# N32L406 register map
Vendor: Nationstech Ltd.; File version: 1.0
Registers are 32-bit, read-write, reset 0x0 unless marked. A register's access mark holds for its fields unless they carry their own. Offsets are from the block's base; [hi:lo] are bit positions; lines under a group give offsets from that group; {n}, {i} and the like mark numbered series.

## NVIC — Nested Vectored Interrupt Controller registers
Base 0xE000E004
0x00 ICTR ro — Provides information about the interrupt controller
  [3:0] INTLINESNUM — The total number of interrupt lines supported n, defined in groups of 32. That is, the total number of interrupt lines is up to (32*(INTLINESNUM+1)). However, the absolute maximum number of interrupts is 496, corresponding to the INTLINESNUM value 0b1111.
0x252 NVIC_ISER0 — Enables, or reads the enable state of a group of interrupts
0x256 NVIC_ISER1 — Enables, or reads the enable state of a group of interrupts
{0x258+4i} NVIC_ISER{i} (i=2..4) — Enables, or reads the enable state of a group of interrupts
0x272 NVIC_ISER5 — Enables, or reads the enable state of a group of interrupts
0x276 NVIC_ISER6 — Enables, or reads the enable state of a group of interrupts
0x280 NVIC_ISER7 — Enables, or reads the enable state of a group of interrupts
{0x380+4i} NVIC_ICER{i} (i=0..2) — Disables, or reads the enable state of a group of interrupts
0x392 NVIC_ICER3 — Disables, or reads the enable state of a group of interrupts
0x396 NVIC_ICER4 — Disables, or reads the enable state of a group of interrupts
{0x3EC+4i} NVIC_ICER{i} (i=5..7) — Disables, or reads the enable state of a group of interrupts
0x508 NVIC_ISPR0 — For a group of interrupts, changes interrupt status to pending, or shows the current pending status
0x512 NVIC_ISPR1 — For a group of interrupts, changes interrupt status to pending, or shows the current pending status
0x516 NVIC_ISPR2 — For a group of interrupts, changes interrupt status to pending, or shows the current pending status
{0x514+4i} NVIC_ISPR{i} (i=3..5) — For a group of interrupts, changes interrupt status to pending, or shows the current pending status
0x532 NVIC_ISPR6 — For a group of interrupts, changes interrupt status to pending, or shows the current pending status
0x536 NVIC_ISPR7 — For a group of interrupts, changes interrupt status to pending, or shows the current pending status
0x636 NVIC_ICPR0 — For a group of interrupts, clears the interrupt pending status, or shows the current pending status
{0x63C+4i} NVIC_ICPR{i} (i=1..3) — For a group of interrupts, clears the interrupt pending status, or shows the current pending status
0x652 NVIC_ICPR4 — For a group of interrupts, clears the interrupt pending status, or shows the current pending status
0x656 NVIC_ICPR5 — For a group of interrupts, clears the interrupt pending status, or shows the current pending status
0x660 NVIC_ICPR6 — For a group of interrupts, clears the interrupt pending status, or shows the current pending status
0x664 NVIC_ICPR7 — For a group of interrupts, clears the interrupt pending status, or shows the current pending status
0x764 NVIC_IABR0 — For a group of 32 interrupts, shows whether each interrupt is active
0x768 NVIC_IABR1 — For a group of 32 interrupts, shows whether each interrupt is active
0x772 NVIC_IABR2 — For a group of 32 interrupts, shows whether each interrupt is active
0x776 NVIC_IABR3 — For a group of 32 interrupts, shows whether each interrupt is active
{0x770+4i} NVIC_IABR{i} (i=4..6) — For a group of 32 interrupts, shows whether each interrupt is active
0x792 NVIC_IABR7 — For a group of 32 interrupts, shows whether each interrupt is active
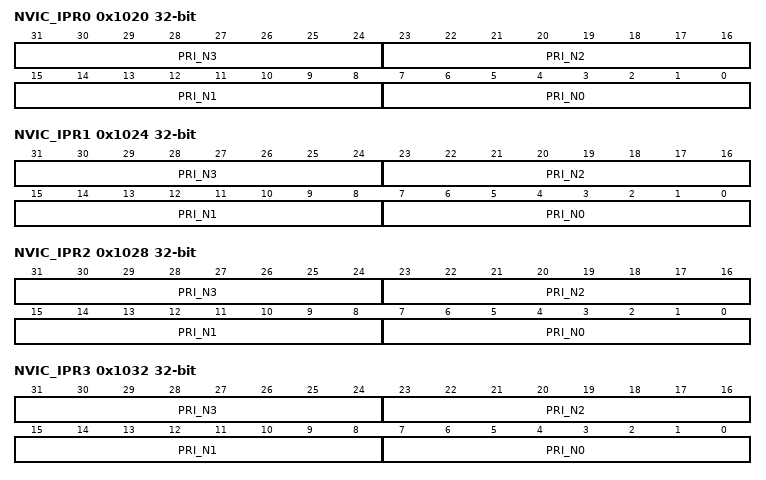
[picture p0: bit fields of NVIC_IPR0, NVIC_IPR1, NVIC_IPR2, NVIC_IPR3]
0x1020 NVIC_IPR0 — Sets or reads interrupt priorities
  [8n+7:8n] PRI_N{n} (n=0..3) — Priority of interrupt {n}
0x1024 NVIC_IPR1 — Sets or reads interrupt priorities
  [8n+7:8n] PRI_N{n} (n=0..3) — Priority of interrupt {n+4}
0x1028 NVIC_IPR2 — Sets or reads interrupt priorities
  [8n+7:8n] PRI_N{n} (n=0..3) — Priority of interrupt {n+8}
0x1032 NVIC_IPR3 — Sets or reads interrupt priorities
  [8n+7:8n] PRI_N{n} (n=0..3) — Priority of interrupt {n+12}
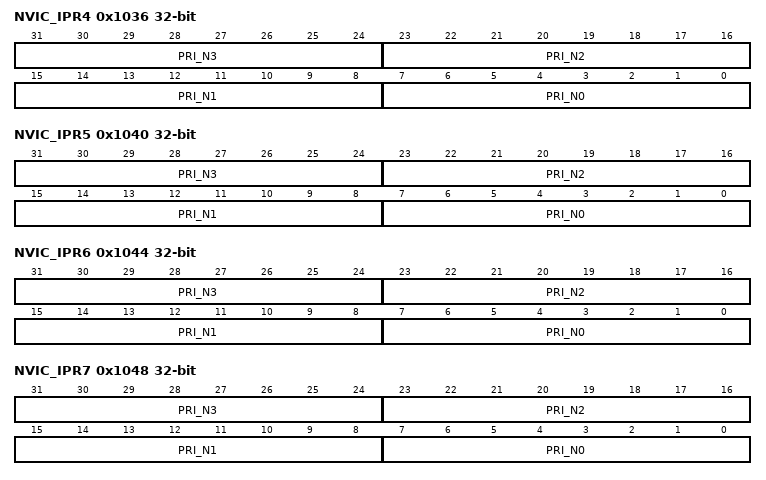
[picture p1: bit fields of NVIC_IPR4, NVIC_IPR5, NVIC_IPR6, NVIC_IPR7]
0x1036 NVIC_IPR4 — Sets or reads interrupt priorities
  [8n+7:8n] PRI_N{n} (n=0..3) — Priority of interrupt {n+16}
0x1040 NVIC_IPR5 — Sets or reads interrupt priorities
  [8n+7:8n] PRI_N{n} (n=0..3) — Priority of interrupt {n+20}
0x1044 NVIC_IPR6 — Sets or reads interrupt priorities
  [8n+7:8n] PRI_N{n} (n=0..3) — Priority of interrupt {n+24}
0x1048 NVIC_IPR7 — Sets or reads interrupt priorities
  [8n+7:8n] PRI_N{n} (n=0..3) — Priority of interrupt {n+28}
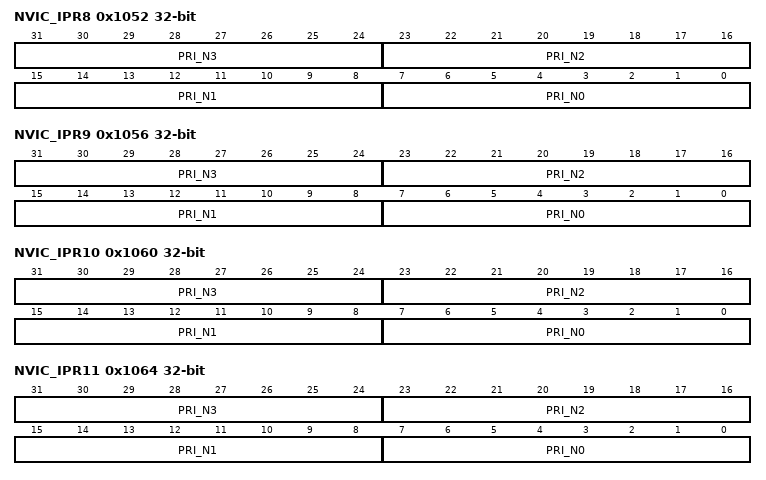
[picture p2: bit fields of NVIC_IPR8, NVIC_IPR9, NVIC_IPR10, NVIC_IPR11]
0x1052 NVIC_IPR8 — Sets or reads interrupt priorities
  [8n+7:8n] PRI_N{n} (n=0..3) — Priority of interrupt {n+32}
0x1056 NVIC_IPR9 — Sets or reads interrupt priorities
  [8n+7:8n] PRI_N{n} (n=0..3) — Priority of interrupt {n+36}
0x1060 NVIC_IPR10 — Sets or reads interrupt priorities
  [8n+7:8n] PRI_N{n} (n=0..3) — Priority of interrupt {n+40}
0x1064 NVIC_IPR11 — Sets or reads interrupt priorities
  [8n+7:8n] PRI_N{n} (n=0..3) — Priority of interrupt {n+44}
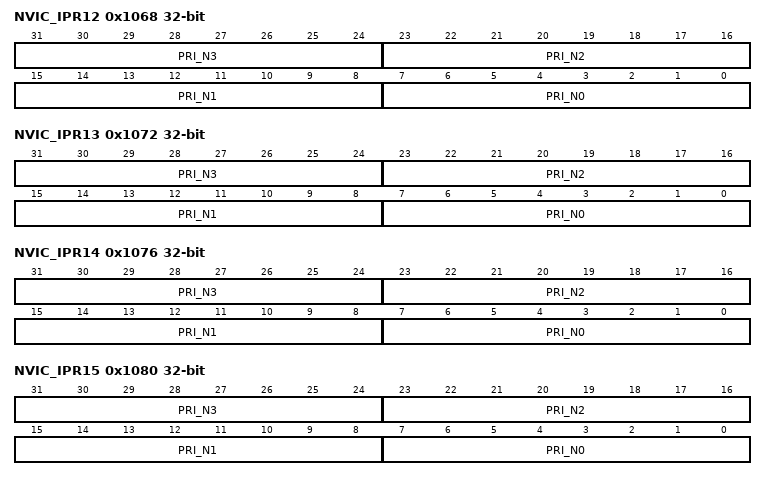
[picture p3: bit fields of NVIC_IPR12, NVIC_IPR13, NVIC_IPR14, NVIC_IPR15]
0x1068 NVIC_IPR12 — Sets or reads interrupt priorities
  [8n+7:8n] PRI_N{n} (n=0..3) — Priority of interrupt {n+48}
0x1072 NVIC_IPR13 — Sets or reads interrupt priorities
  [8n+7:8n] PRI_N{n} (n=0..3) — Priority of interrupt {n+52}
0x1076 NVIC_IPR14 — Sets or reads interrupt priorities
  [8n+7:8n] PRI_N{n} (n=0..3) — Priority of interrupt {n+56}
0x1080 NVIC_IPR15 — Sets or reads interrupt priorities
  [8n+7:8n] PRI_N{n} (n=0..3) — Priority of interrupt {n+60}
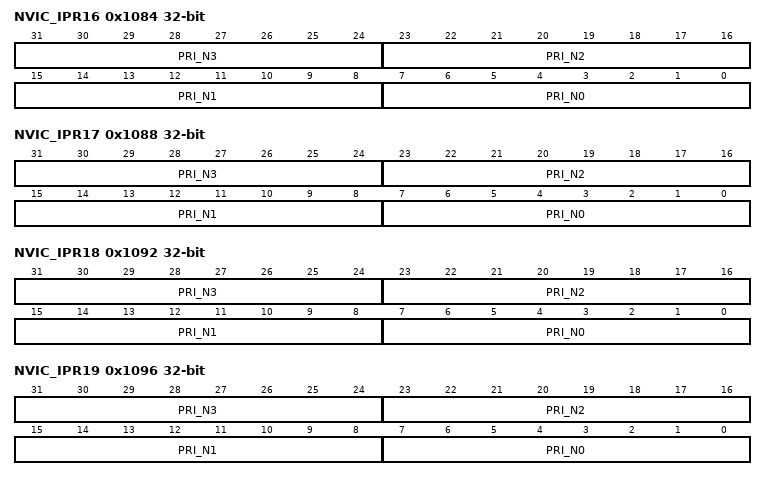
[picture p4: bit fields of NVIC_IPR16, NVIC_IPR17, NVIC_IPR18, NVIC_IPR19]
0x1084 NVIC_IPR16 — Sets or reads interrupt priorities
  [8n+7:8n] PRI_N{n} (n=0..3) — Priority of interrupt {n+64}
0x1088 NVIC_IPR17 — Sets or reads interrupt priorities
  [8n+7:8n] PRI_N{n} (n=0..3) — Priority of interrupt {n+68}
0x1092 NVIC_IPR18 — Sets or reads interrupt priorities
  [8n+7:8n] PRI_N{n} (n=0..3) — Priority of interrupt {n+72}
0x1096 NVIC_IPR19 — Sets or reads interrupt priorities
  [8n+7:8n] PRI_N{n} (n=0..3) — Priority of interrupt {n+76}
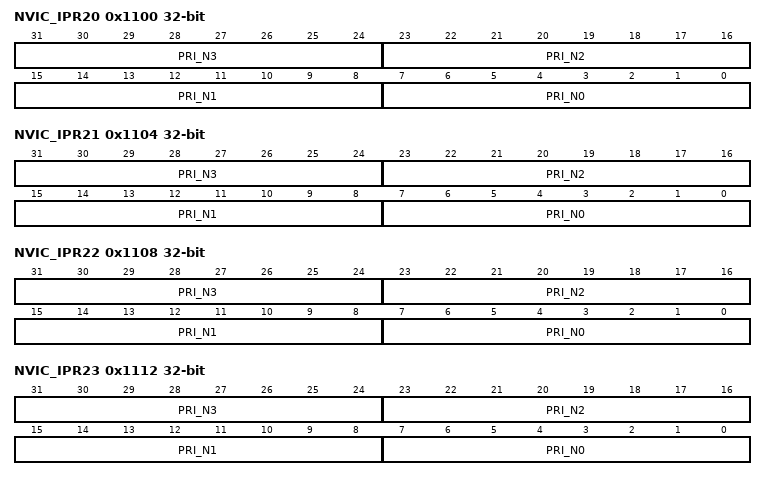
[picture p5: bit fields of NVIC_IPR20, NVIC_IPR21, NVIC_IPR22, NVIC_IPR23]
0x1100 NVIC_IPR20 — Sets or reads interrupt priorities
  [8n+7:8n] PRI_N{n} (n=0..3) — Priority of interrupt {n+80}
0x1104 NVIC_IPR21 — Sets or reads interrupt priorities
  [8n+7:8n] PRI_N{n} (n=0..3) — Priority of interrupt {n+84}
0x1108 NVIC_IPR22 — Sets or reads interrupt priorities
  [8n+7:8n] PRI_N{n} (n=0..3) — Priority of interrupt {n+88}
0x1112 NVIC_IPR23 — Sets or reads interrupt priorities
  [8n+7:8n] PRI_N{n} (n=0..3) — Priority of interrupt {n+92}
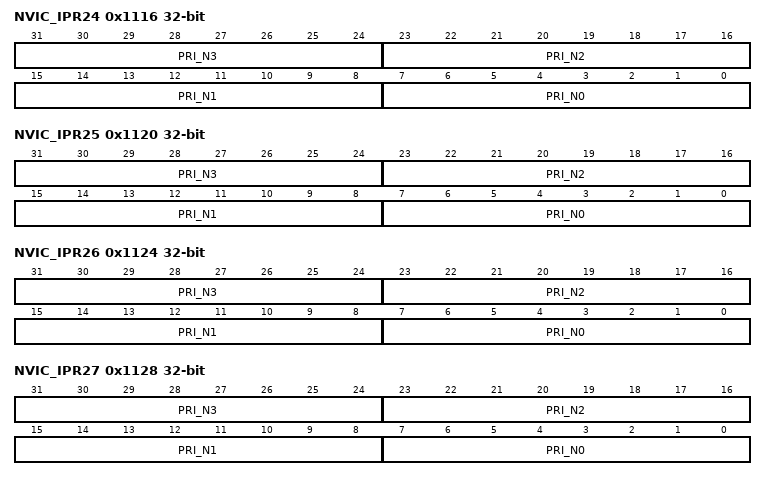
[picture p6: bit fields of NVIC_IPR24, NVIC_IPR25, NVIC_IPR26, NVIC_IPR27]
0x1116 NVIC_IPR24 — Sets or reads interrupt priorities
  [8n+7:8n] PRI_N{n} (n=0..3) — Priority of interrupt {n+96}
0x1120 NVIC_IPR25 — Sets or reads interrupt priorities
  [8n+7:8n] PRI_N{n} (n=0..3) — Priority of interrupt {n+100}
0x1124 NVIC_IPR26 — Sets or reads interrupt priorities
  [8n+7:8n] PRI_N{n} (n=0..3) — Priority of interrupt {n+104}
0x1128 NVIC_IPR27 — Sets or reads interrupt priorities
  [8n+7:8n] PRI_N{n} (n=0..3) — Priority of interrupt {n+108}
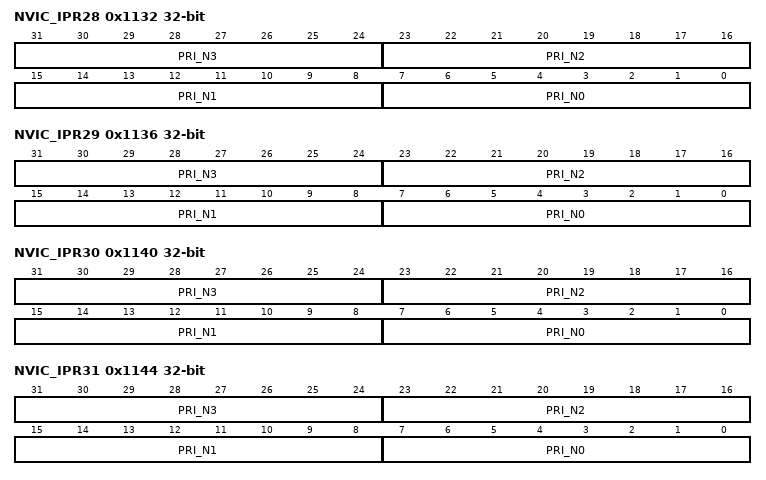
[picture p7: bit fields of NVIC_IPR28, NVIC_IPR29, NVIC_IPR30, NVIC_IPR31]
0x1132 NVIC_IPR28 — Sets or reads interrupt priorities
  [8n+7:8n] PRI_N{n} (n=0..3) — Priority of interrupt {n+112}
0x1136 NVIC_IPR29 — Sets or reads interrupt priorities
  [8n+7:8n] PRI_N{n} (n=0..3) — Priority of interrupt {n+116}
0x1140 NVIC_IPR30 — Sets or reads interrupt priorities
  [8n+7:8n] PRI_N{n} (n=0..3) — Priority of interrupt {n+120}
0x1144 NVIC_IPR31 — Sets or reads interrupt priorities
  [8n+7:8n] PRI_N{n} (n=0..3) — Priority of interrupt {n+124}
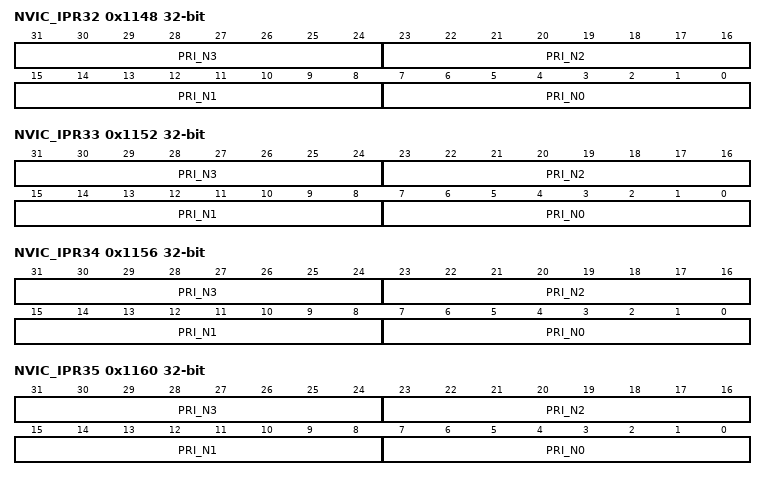
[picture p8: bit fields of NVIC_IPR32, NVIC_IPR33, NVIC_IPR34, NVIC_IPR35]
0x1148 NVIC_IPR32 — Sets or reads interrupt priorities
  [8n+7:8n] PRI_N{n} (n=0..3) — Priority of interrupt {n+128}
0x1152 NVIC_IPR33 — Sets or reads interrupt priorities
  [8n+7:8n] PRI_N{n} (n=0..3) — Priority of interrupt {n+132}
0x1156 NVIC_IPR34 — Sets or reads interrupt priorities
  [8n+7:8n] PRI_N{n} (n=0..3) — Priority of interrupt {n+136}
0x1160 NVIC_IPR35 — Sets or reads interrupt priorities
  [8n+7:8n] PRI_N{n} (n=0..3) — Priority of interrupt {n+140}
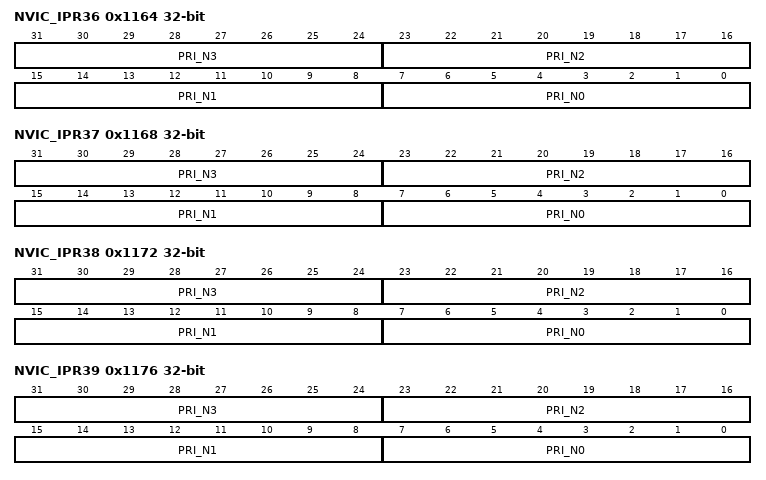
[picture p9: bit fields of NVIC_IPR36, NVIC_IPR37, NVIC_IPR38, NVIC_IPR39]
0x1164 NVIC_IPR36 — Sets or reads interrupt priorities
  [8n+7:8n] PRI_N{n} (n=0..3) — Priority of interrupt {n+144}
0x1168 NVIC_IPR37 — Sets or reads interrupt priorities
  [8n+7:8n] PRI_N{n} (n=0..3) — Priority of interrupt {n+148}
0x1172 NVIC_IPR38 — Sets or reads interrupt priorities
  [8n+7:8n] PRI_N{n} (n=0..3) — Priority of interrupt {n+152}
0x1176 NVIC_IPR39 — Sets or reads interrupt priorities
  [8n+7:8n] PRI_N{n} (n=0..3) — Priority of interrupt {n+156}
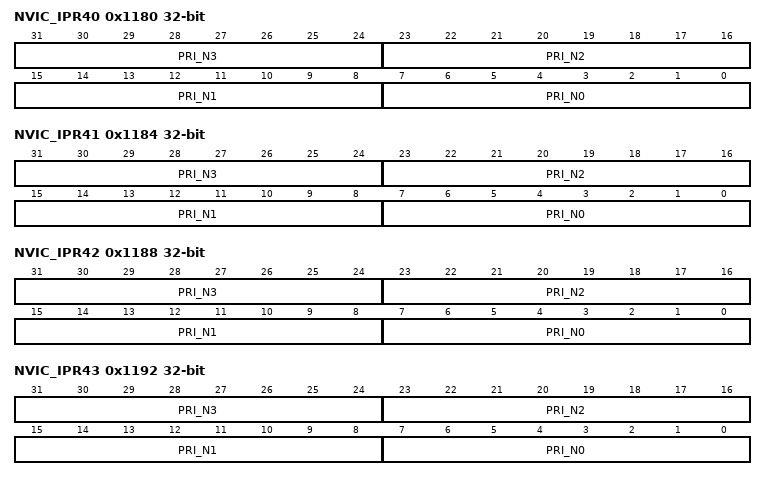
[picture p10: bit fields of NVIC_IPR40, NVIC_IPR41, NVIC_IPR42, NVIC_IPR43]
0x1180 NVIC_IPR40 — Sets or reads interrupt priorities
  [8n+7:8n] PRI_N{n} (n=0..3) — Priority of interrupt {n+160}
0x1184 NVIC_IPR41 — Sets or reads interrupt priorities
  [8n+7:8n] PRI_N{n} (n=0..3) — Priority of interrupt {n+164}
0x1188 NVIC_IPR42 — Sets or reads interrupt priorities
  [8n+7:8n] PRI_N{n} (n=0..3) — Priority of interrupt {n+168}
0x1192 NVIC_IPR43 — Sets or reads interrupt priorities
  [8n+7:8n] PRI_N{n} (n=0..3) — Priority of interrupt {n+172}
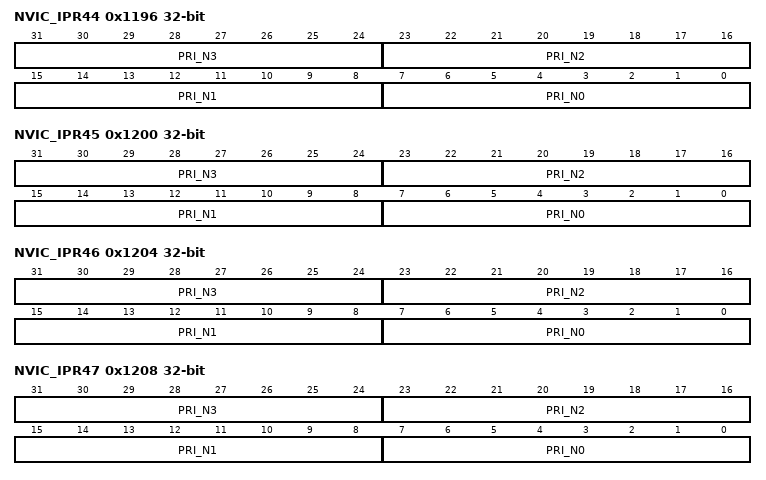
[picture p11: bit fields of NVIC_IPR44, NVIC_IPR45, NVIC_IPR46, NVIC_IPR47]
0x1196 NVIC_IPR44 — Sets or reads interrupt priorities
  [8n+7:8n] PRI_N{n} (n=0..3) — Priority of interrupt {n+176}
0x1200 NVIC_IPR45 — Sets or reads interrupt priorities
  [8n+7:8n] PRI_N{n} (n=0..3) — Priority of interrupt {n+180}
0x1204 NVIC_IPR46 — Sets or reads interrupt priorities
  [8n+7:8n] PRI_N{n} (n=0..3) — Priority of interrupt {n+184}
0x1208 NVIC_IPR47 — Sets or reads interrupt priorities
  [8n+7:8n] PRI_N{n} (n=0..3) — Priority of interrupt {n+188}
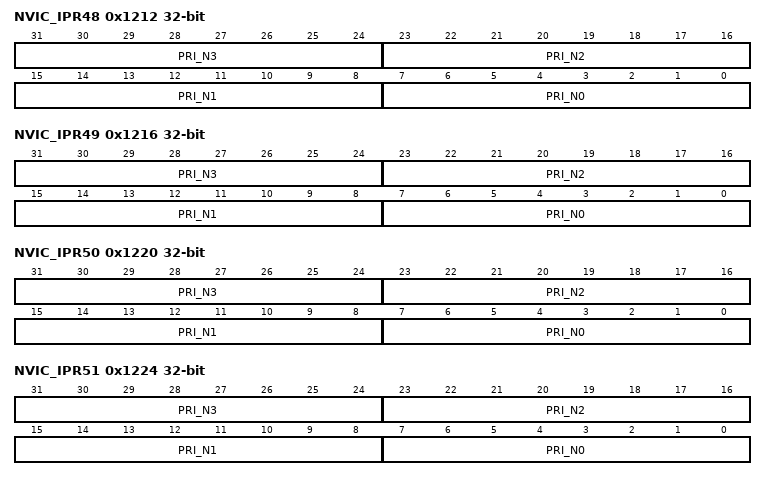
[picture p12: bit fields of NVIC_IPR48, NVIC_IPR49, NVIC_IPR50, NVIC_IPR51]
0x1212 NVIC_IPR48 — Sets or reads interrupt priorities
  [8n+7:8n] PRI_N{n} (n=0..3) — Priority of interrupt {n+192}
0x1216 NVIC_IPR49 — Sets or reads interrupt priorities
  [8n+7:8n] PRI_N{n} (n=0..3) — Priority of interrupt {n+196}
0x1220 NVIC_IPR50 — Sets or reads interrupt priorities
  [8n+7:8n] PRI_N{n} (n=0..3) — Priority of interrupt {n+200}
0x1224 NVIC_IPR51 — Sets or reads interrupt priorities
  [8n+7:8n] PRI_N{n} (n=0..3) — Priority of interrupt {n+204}
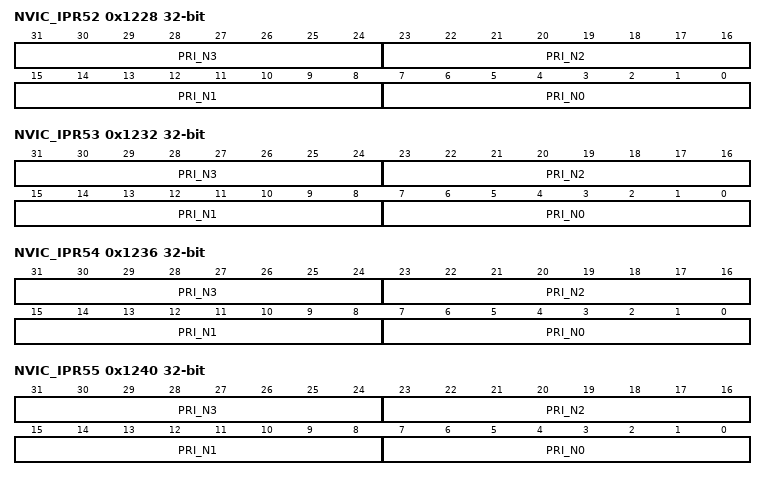
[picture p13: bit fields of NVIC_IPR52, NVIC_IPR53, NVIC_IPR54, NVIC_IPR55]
0x1228 NVIC_IPR52 — Sets or reads interrupt priorities
  [8n+7:8n] PRI_N{n} (n=0..3) — Priority of interrupt {n+208}
0x1232 NVIC_IPR53 — Sets or reads interrupt priorities
  [8n+7:8n] PRI_N{n} (n=0..3) — Priority of interrupt {n+212}
0x1236 NVIC_IPR54 — Sets or reads interrupt priorities
  [8n+7:8n] PRI_N{n} (n=0..3) — Priority of interrupt {n+216}
0x1240 NVIC_IPR55 — Sets or reads interrupt priorities
  [8n+7:8n] PRI_N{n} (n=0..3) — Priority of interrupt {n+220}
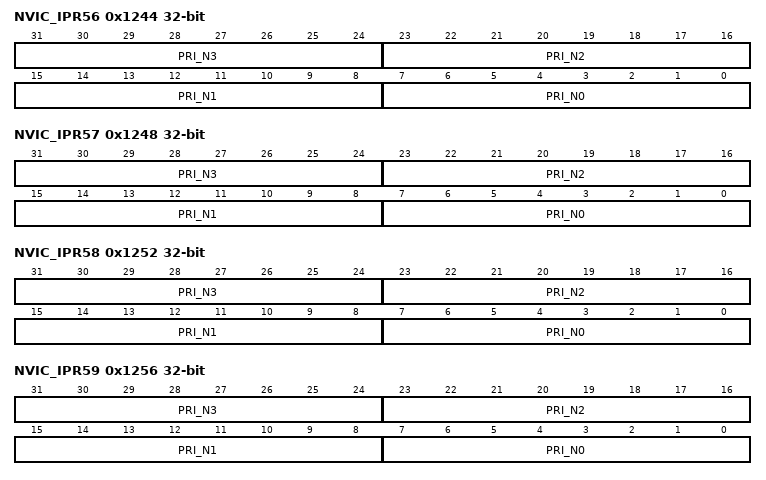
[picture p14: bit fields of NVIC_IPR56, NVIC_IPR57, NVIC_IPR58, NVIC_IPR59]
0x1244 NVIC_IPR56 — Sets or reads interrupt priorities
  [8n+7:8n] PRI_N{n} (n=0..3) — Priority of interrupt {n+224}
0x1248 NVIC_IPR57 — Sets or reads interrupt priorities
  [8n+7:8n] PRI_N{n} (n=0..3) — Priority of interrupt {n+228}
0x1252 NVIC_IPR58 — Sets or reads interrupt priorities
  [8n+7:8n] PRI_N{n} (n=0..3) — Priority of interrupt {n+232}
0x1256 NVIC_IPR59 — Sets or reads interrupt priorities
  [8n+7:8n] PRI_N{n} (n=0..3) — Priority of interrupt {n+236}
